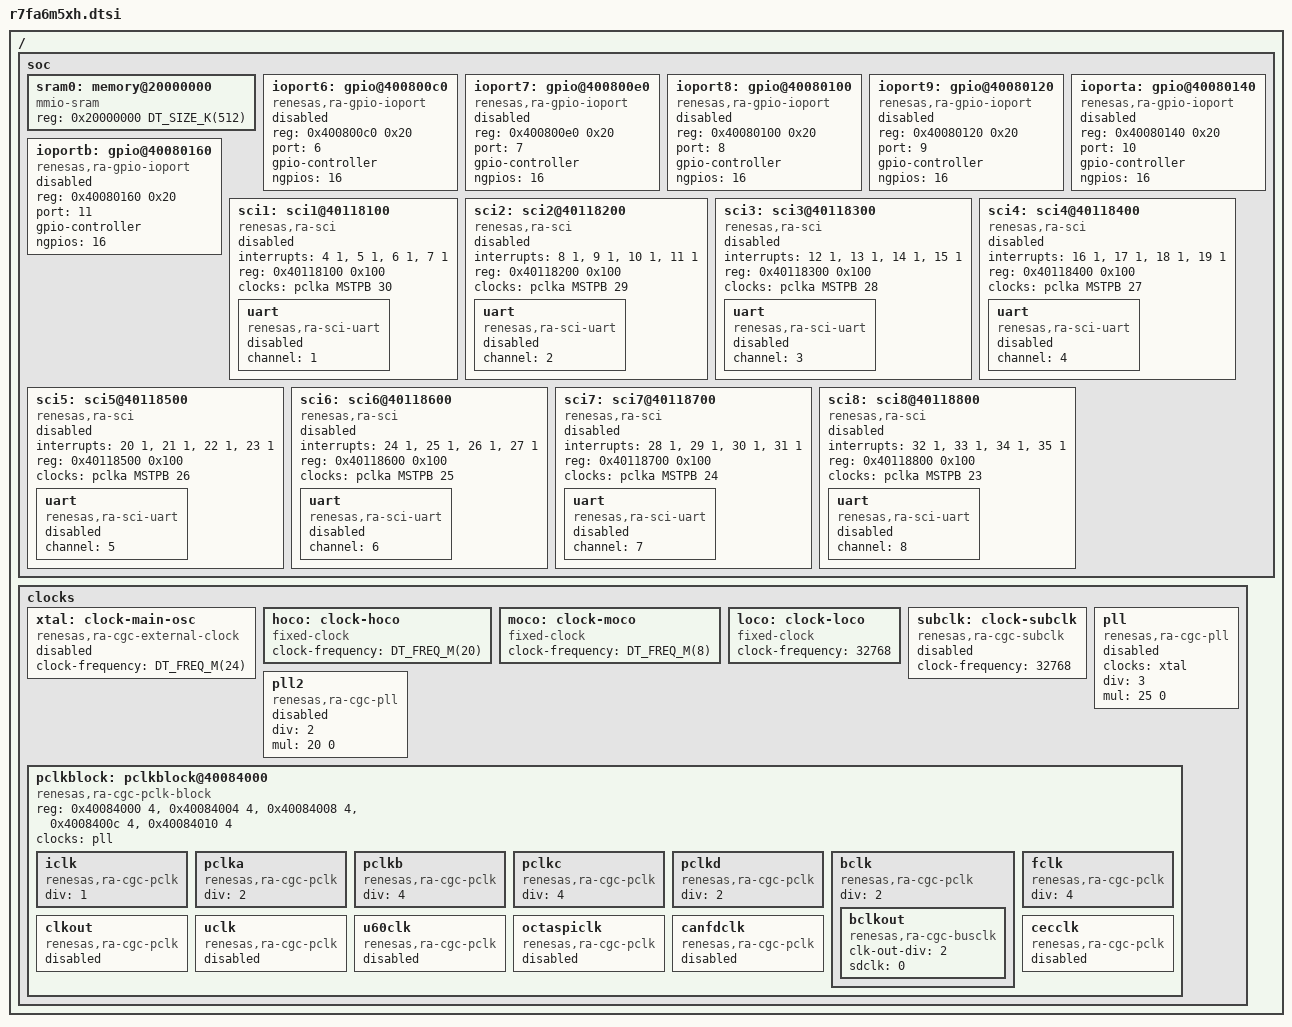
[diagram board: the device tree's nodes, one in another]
/*
 * Copyright (c) 2024 Renesas Electronics Corporation
 *
 * SPDX-License-Identifier: Apache-2.0
 */

#include <arm/renesas/ra/ra6/ra6-cm33-common.dtsi>
#include <zephyr/dt-bindings/clock/ra_clock.h>

/ {
	soc {
		sram0: memory@20000000 {
			compatible = "mmio-sram";
			reg = <0x20000000 DT_SIZE_K(512)>;
		};

		ioport6: gpio@400800c0 {
			compatible = "renesas,ra-gpio-ioport";
			reg = <0x400800c0 0x20>;
			port = <6>;
			gpio-controller;
			#gpio-cells = <2>;
			ngpios = <16>;
			status = "disabled";
		};

		ioport7: gpio@400800e0 {
			compatible = "renesas,ra-gpio-ioport";
			reg = <0x400800e0 0x20>;
			port = <7>;
			gpio-controller;
			#gpio-cells = <2>;
			ngpios = <16>;
			status = "disabled";
		};

		ioport8: gpio@40080100 {
			compatible = "renesas,ra-gpio-ioport";
			reg = <0x40080100 0x20>;
			port = <8>;
			gpio-controller;
			#gpio-cells = <2>;
			ngpios = <16>;
			status = "disabled";
		};

		ioport9: gpio@40080120 {
			compatible = "renesas,ra-gpio-ioport";
			reg = <0x40080120 0x20>;
			port = <9>;
			gpio-controller;
			#gpio-cells = <2>;
			ngpios = <16>;
			status = "disabled";
		};

		ioporta: gpio@40080140 {
			compatible = "renesas,ra-gpio-ioport";
			reg = <0x40080140 0x20>;
			port = <10>;
			gpio-controller;
			#gpio-cells = <2>;
			ngpios = <16>;
			status = "disabled";
		};

		ioportb: gpio@40080160 {
			compatible = "renesas,ra-gpio-ioport";
			reg = <0x40080160 0x20>;
			port = <11>;
			gpio-controller;
			#gpio-cells = <2>;
			ngpios = <16>;
			status = "disabled";
		};

		sci1: sci1@40118100 {
			compatible = "renesas,ra-sci";
			interrupts = <4 1>, <5 1>, <6 1>, <7 1>;
			interrupt-names = "rxi", "txi", "tei", "eri";
			reg = <0x40118100 0x100>;
			clocks = <&pclka MSTPB 30>;
			status = "disabled";
			uart {
				compatible = "renesas,ra-sci-uart";
				channel = <1>;
				status = "disabled";
			};
		};

		sci2: sci2@40118200 {
			compatible = "renesas,ra-sci";
			interrupts = <8 1>, <9 1>, <10 1>, <11 1>;
			interrupt-names = "rxi", "txi", "tei", "eri";
			reg = <0x40118200 0x100>;
			clocks = <&pclka MSTPB 29>;
			status = "disabled";
			uart {
				compatible = "renesas,ra-sci-uart";
				channel = <2>;
				status = "disabled";
			};
		};

		sci3: sci3@40118300 {
			compatible = "renesas,ra-sci";
			interrupts = <12 1>, <13 1>, <14 1>, <15 1>;
			interrupt-names = "rxi", "txi", "tei", "eri";
			reg = <0x40118300 0x100>;
			clocks = <&pclka MSTPB 28>;
			status = "disabled";
			uart {
				compatible = "renesas,ra-sci-uart";
				channel = <3>;
				status = "disabled";
			};
		};

		sci4: sci4@40118400 {
			compatible = "renesas,ra-sci";
			interrupts = <16 1>, <17 1>, <18 1>, <19 1>;
			interrupt-names = "rxi", "txi", "tei", "eri";
			reg = <0x40118400 0x100>;
			clocks = <&pclka MSTPB 27>;
			status = "disabled";
			uart {
				compatible = "renesas,ra-sci-uart";
				channel = <4>;
				status = "disabled";
			};
		};

		sci5: sci5@40118500 {
			compatible = "renesas,ra-sci";
			interrupts = <20 1>, <21 1>, <22 1>, <23 1>;
			interrupt-names = "rxi", "txi", "tei", "eri";
			reg = <0x40118500 0x100>;
			clocks = <&pclka MSTPB 26>;
			status = "disabled";
			uart {
				compatible = "renesas,ra-sci-uart";
				channel = <5>;
				status = "disabled";
			};
		};

		sci6: sci6@40118600 {
			compatible = "renesas,ra-sci";
			interrupts = <24 1>, <25 1>, <26 1>, <27 1>;
			interrupt-names = "rxi", "txi", "tei", "eri";
			reg = <0x40118600 0x100>;
			clocks = <&pclka MSTPB 25>;
			status = "disabled";
			uart {
				compatible = "renesas,ra-sci-uart";
				channel = <6>;
				status = "disabled";
			};
		};

		sci7: sci7@40118700 {
			compatible = "renesas,ra-sci";
			interrupts = <28 1>, <29 1>, <30 1>, <31 1>;
			interrupt-names = "rxi", "txi", "tei", "eri";
			reg = <0x40118700 0x100>;
			clocks = <&pclka MSTPB 24>;
			status = "disabled";
			uart {
				compatible = "renesas,ra-sci-uart";
				channel = <7>;
				status = "disabled";
			};
		};

		sci8: sci8@40118800 {
			compatible = "renesas,ra-sci";
			interrupts = <32 1>, <33 1>, <34 1>, <35 1>;
			interrupt-names = "rxi", "txi", "tei", "eri";
			reg = <0x40118800 0x100>;
			clocks = <&pclka MSTPB 23>;
			status = "disabled";
			uart {
				compatible = "renesas,ra-sci-uart";
				channel = <8>;
				status = "disabled";
			};
		};
	};

	clocks: clocks {
		#address-cells = <1>;
		#size-cells = <1>;

		xtal: clock-main-osc {
			compatible = "renesas,ra-cgc-external-clock";
			clock-frequency = <DT_FREQ_M(24)>;
			#clock-cells = <0>;
			status = "disabled";
		};

		hoco: clock-hoco {
			compatible = "fixed-clock";
			clock-frequency = <DT_FREQ_M(20)>;
			#clock-cells = <0>;
		};

		moco: clock-moco {
			compatible = "fixed-clock";
			clock-frequency = <DT_FREQ_M(8)>;
			#clock-cells = <0>;
		};

		loco: clock-loco {
			compatible = "fixed-clock";
			clock-frequency = <32768>;
			#clock-cells = <0>;
		};

		subclk: clock-subclk {
			compatible = "renesas,ra-cgc-subclk";
			clock-frequency = <32768>;
			#clock-cells = <0>;
			status = "disabled";
		};

		pll: pll {
			compatible = "renesas,ra-cgc-pll";
			#clock-cells = <0>;

			/* PLL */
			clocks = <&xtal>;
			div = <3>;
			mul = <25 0>;
			status = "disabled";
		};

		pll2: pll2 {
			compatible = "renesas,ra-cgc-pll";
			#clock-cells = <0>;

			/* PLL2 */
			div = <2>;
			mul = <20 0>;
			status = "disabled";
		};

		pclkblock: pclkblock@40084000 {
			compatible = "renesas,ra-cgc-pclk-block";
			reg = <0x40084000 4>, <0x40084004 4>, <0x40084008 4>,
			      <0x4008400c 4>, <0x40084010 4>;
			reg-names = "MSTPA", "MSTPB","MSTPC",
				    "MSTPD", "MSTPE";
			#clock-cells = <0>;
			clocks = <&pll>;
			status = "okay";

			iclk: iclk {
				compatible = "renesas,ra-cgc-pclk";
				div = <1>;
				#clock-cells = <2>;
				status = "okay";
			};

			pclka: pclka {
				compatible = "renesas,ra-cgc-pclk";
				div = <2>;
				#clock-cells = <2>;
				status = "okay";
			};

			pclkb: pclkb {
				compatible = "renesas,ra-cgc-pclk";
				div = <4>;
				#clock-cells = <2>;
				status = "okay";
			};

			pclkc: pclkc {
				compatible = "renesas,ra-cgc-pclk";
				div = <4>;
				#clock-cells = <2>;
				status = "okay";
			};

			pclkd: pclkd {
				compatible = "renesas,ra-cgc-pclk";
				div = <2>;
				#clock-cells = <2>;
				status = "okay";
			};

			bclk: bclk {
				compatible = "renesas,ra-cgc-pclk";
				div = <2>;
				bclkout: bclkout {
					compatible = "renesas,ra-cgc-busclk";
					clk-out-div = <2>;
					sdclk = <0>;
					#clock-cells = <0>;
				};
				#clock-cells = <2>;
				status = "okay";
			};

			fclk: fclk {
				compatible = "renesas,ra-cgc-pclk";
				div = <4>;
				#clock-cells = <2>;
				status = "okay";
			};

			clkout: clkout {
				compatible = "renesas,ra-cgc-pclk";
				#clock-cells = <2>;
				status = "disabled";
			};

			uclk: uclk {
				compatible = "renesas,ra-cgc-pclk";
				#clock-cells = <2>;
				status = "disabled";
			};

			u60clk: u60clk {
				compatible = "renesas,ra-cgc-pclk";
				#clock-cells = <2>;
				status = "disabled";
			};

			octaspiclk: octaspiclk {
				compatible = "renesas,ra-cgc-pclk";
				#clock-cells = <2>;
				status = "disabled";
			};

			canfdclk: canfdclk {
				compatible = "renesas,ra-cgc-pclk";
				#clock-cells = <2>;
				status = "disabled";
			};

			cecclk: cecclk {
				compatible = "renesas,ra-cgc-pclk";
				#clock-cells = <2>;
				status = "disabled";
			};
		};
	};
};
